# skbd_reva_me55 register map
Registers are access not given, no defined reset value unless marked. A register's access mark holds for its fields unless they carry their own. Offsets are from the block's base; lines under a group give offsets from that group; [hi:lo] are bit positions; {n}, {i} and the like mark numbered series; 'fields as' and 'values as' point back to an identical list; <NAME> marks a mode.

## Memory map
0x40032000 SKBD size 0x1000 — Secure Keyboard

## Interrupts
19 Secure_Keypad (SKBD) — Secure Keypad interrupt

## SKBD — Secure Keyboard
Base 0x40032000
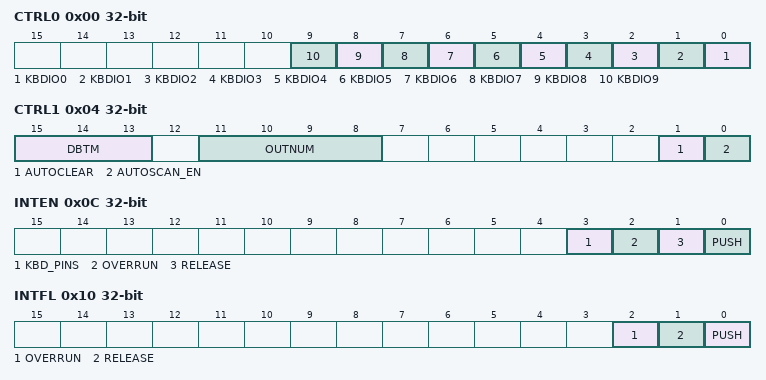
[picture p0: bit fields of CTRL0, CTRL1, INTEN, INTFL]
0x00 CTRL0 — Input Output Select Bits. Each bit of IOSEL selects the pin direction for the corresponding KBDIO pin. If IOSEL[0] = 1, KBDIO0 is an output.
  [all] fields
    0=input; 1=output
  [n] KBDIO{n} (n=0..9) — Input Output Select for KBDIO{n} pin.
0x04 CTRL1 — Control Register 1
  [15:13] DBTM — Debounce Time. Number of milliseconds a keypress event must be active before it is considered actual. NOTE: Debounce time values based on system running from an external 12MHz clock source with PLL0 enabled. Other external crystal values will cause the debounce time to scale linearly.
    0=time4ms (4.1 ms); 1=time5ms (5.3 ms); 2=time6ms (6.5 ms); 3=time7ms (7.6 ms); 4=time8ms (8.8 ms); 5=time10ms (10.0 ms); 6=time11ms (11.2 ms); 7=time12ms (12.3 ms)
  [11:8] OUTNUM — Output Number. Number of KBDIO pins selected as outputs. NOTE: Output pins must be allocated contiguously starting with KBDIO0 and continuing through to KBDIO7.
  [1] AUTOCLEAR — Auto Clear Bit
    0=disable; 1=enable
  [0] AUTOSCAN_EN — Automatic Keyboard Scan Enable
    0=disable; 1=enable
0x08 STATUS ro
  [0] BUSY — Busy bit. This bit is set by hardware when the automatic keyboard scan is enabled and running. This bit is clear at all other times.
    0=idle; 1=busy
0x0C INTEN — Interrupt Enable Register
  [3] KBD_PINS — Keyboard Pins Interrupt Enable.
  [2] OVERRUN — Overrun Event Enable Bit. When set, this bit enables an interrupt to be generated on an overrun event. Automatic keyboard scan must be enabled.
    0=disable; 1=enable
  [1] RELEASE — Release Event Enable Bit. When set, this bit enables an interrupt to be generated on a key release event. Automatic keyboard scan must be enabled.
    0=disable; 1=enable
  [0] PUSH — Push Event Enable Bit. When set, this bit enables an interrupt to be generated on a key push event. Automatic keyboard scan must be enabled.
    0=disable; 1=enable
0x10 INTFL — Interrupt Status Register
  [all] fields
    0=inactive (No interrupt is pending.); 1=pending (An interrupt is pending.)
  [2] OVERRUN — Overrun Event Enable Bit. This bit is set by hardware when an overrun event has occurred. If the interrupt is enabled for this flag, a system interrupt will be fired. If the interrupt enable is not set, the flag will be set, but no interrupt will fire. This bit must be cleared by software.
  [1] RELEASE — Release Interrupt Flag. This bit is set by hardware when a key has been released. If the interrupt is enabled for this flag, a system interrupt will be fired. If the interrupt enable is not set, the flag will be set, but no interrupt will fire. This bit must be cleared by software.
  [0] PUSH — Push Interrupt Flag. This bit is set by hardware when a key has been pushed. If the interrupt is enabled for this flag, a system interrupt will be fired. If the interrupt enable is not set, the flag will be set, but no interrupt will fire. This bit must be cleared by software.
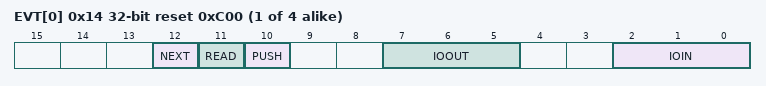
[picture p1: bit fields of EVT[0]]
{0x14+4i} EVT[{i}] (i=0..3) ro reset 0xC00 — Key Register
  [12] NEXT — If set to 1 one of the next key registers (x+1 to 3) contains a key event.
    0=none (No more key register contain a key event.); 1=more (Other key registers contain a key event.)
  [11] READ — If set to 1 this register has been read. If set to 0 the key register has not been read since its last change.
    0=notRead (This register has not been read since its last change.); 1=read (This register has been read.)
  [10] PUSH — If set to 1 the key has been released. If set to 0 the key has been pushed.
    0=pushed; 1=released
  [7:5] IOOUT — IO Output. Output pin of key event.
  [2:0] IOIN — IO Input. Input pin of key event.
0x24 GPIO0 — General Purpose Register 0.
  [31:0] ALL — Mask of all of the pins on the port.
0x28 GPIO1 — General Purpose Register 1.
  [31:0] ALL — Mask of all of the pins on the port.
